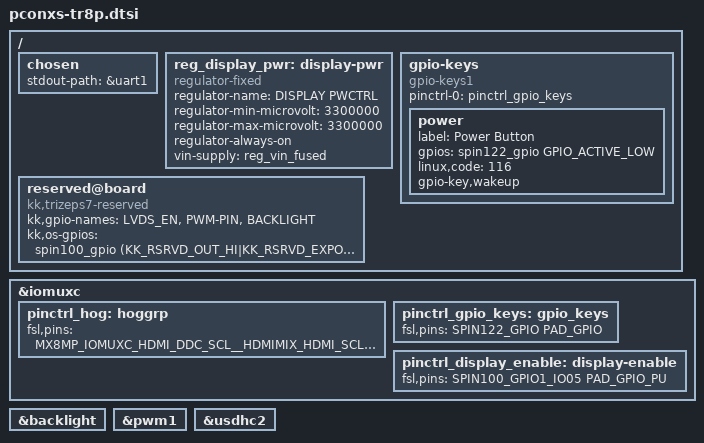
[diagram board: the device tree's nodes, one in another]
/*
 * Copyright 2022 Keith & Koep GmbH
 *
 */

 /************************************************************************/

#ifndef PCONXS_TR8P_DTSI
#define PCONXS_TR8P_DTSI

#ifndef DISPLAY_ONLY_18BPP
#define DISPLAY_ONLY_18BPP          0
#endif

/ {
	chosen {
		stdout-path = &uart1;
	};

	reg_display_pwr: display-pwr {
		compatible = "regulator-fixed";
		regulator-name = "DISPLAY PWCTRL";
		regulator-min-microvolt = <3300000>;
		regulator-max-microvolt = <3300000>;
		regulator-always-on;
		vin-supply = <&reg_vin_fused>;
	};

	gpio-keys {
        compatible = "gpio-keys1";
        pinctrl-names = "default";
        pinctrl-0 = <&pinctrl_gpio_keys>;
        power { /* Reconfig to power key in Android*/
            label = "Power Button";
            gpios = <spin122_gpio GPIO_ACTIVE_LOW>;
            linux,code = <116>; /* KEY_POWER */
            gpio-key,wakeup;
        };
    };

	reserved@board {
        compatible      = "kk,trizeps7-reserved";
        kk,gpio-names   = "LVDS_EN", "PWM-PIN", "BACKLIGHT";//, "BACKLIGHT2";
        kk,os-gpios     = <
			spin100_gpio   (KK_RSRVD_OUT_HI|KK_RSRVD_EXPORT|KK_RSRVD_REQUEST(1)) /* LVDS_EN   gpio1 5   */
#if DISPLAY_ONLY_18BPP
			spin77_gpio    (KK_RSRVD_OUT_LO|KK_RSRVD_EXPORT|KK_RSRVD_REQUEST(2)) /* PWM Backl gpio1 1   */
#else
			spin77_gpio    (KK_RSRVD_OUT_HI|KK_RSRVD_EXPORT|KK_RSRVD_REQUEST(2)) /* PWM Backl gpio1 1   */
#endif
			//spin114_gpio   (KK_RSRVD_OUT_HI|KK_RSRVD_EXPORT|KK_RSRVD_REQUEST(3)) /* Backlight gpio4 14  */
			spin73_gpio   (KK_RSRVD_OUT_HI|KK_RSRVD_EXPORT|KK_RSRVD_REQUEST(4)) /* Backlight gpio4 31  */
			>;
	};
};

&iomuxc {
	pinctrl_hog: hoggrp {
		fsl,pins = <
			// HDMI
			MX8MP_IOMUXC_HDMI_DDC_SCL__HDMIMIX_HDMI_SCL	0x400001c3
			MX8MP_IOMUXC_HDMI_DDC_SDA__HDMIMIX_HDMI_SDA	0x400001c3
			MX8MP_IOMUXC_HDMI_HPD__HDMIMIX_HDMI_HPD		0x40000019
			MX8MP_IOMUXC_HDMI_CEC__HDMIMIX_HDMI_CEC		0x40000019
			// LCD1_VCC_ON
			SPIN100_GPIO1_IO05	PAD_GPIO
		>;
	};

    pinctrl_gpio_keys: gpio_keys {
		fsl,pins = < SPIN122_GPIO       PAD_GPIO >;  /* PowerButton SODIMM Pin 122 */
	};

	pinctrl_display_enable: display-enable 	{
		//fsl,pins = < DISPLAY_ENABLE		PAD_GPIO_PU >; /* DISPLAY_ENABLE */
		fsl,pins = < SPIN100_GPIO1_IO05		PAD_GPIO_PU >; /* DISPLAY_ENABLE */
	};
};

&backlight {
#if DISPLAY_ONLY_18BPP
	status = "disabled";
#else
	status = "okay";
#endif
};


&pwm1 {
#if DISPLAY_ONLY_18BPP
	status = "disabled";
#else
	status = "okay";
#endif
};

&usdhc2 {
	status = "okay";
};

#endif
